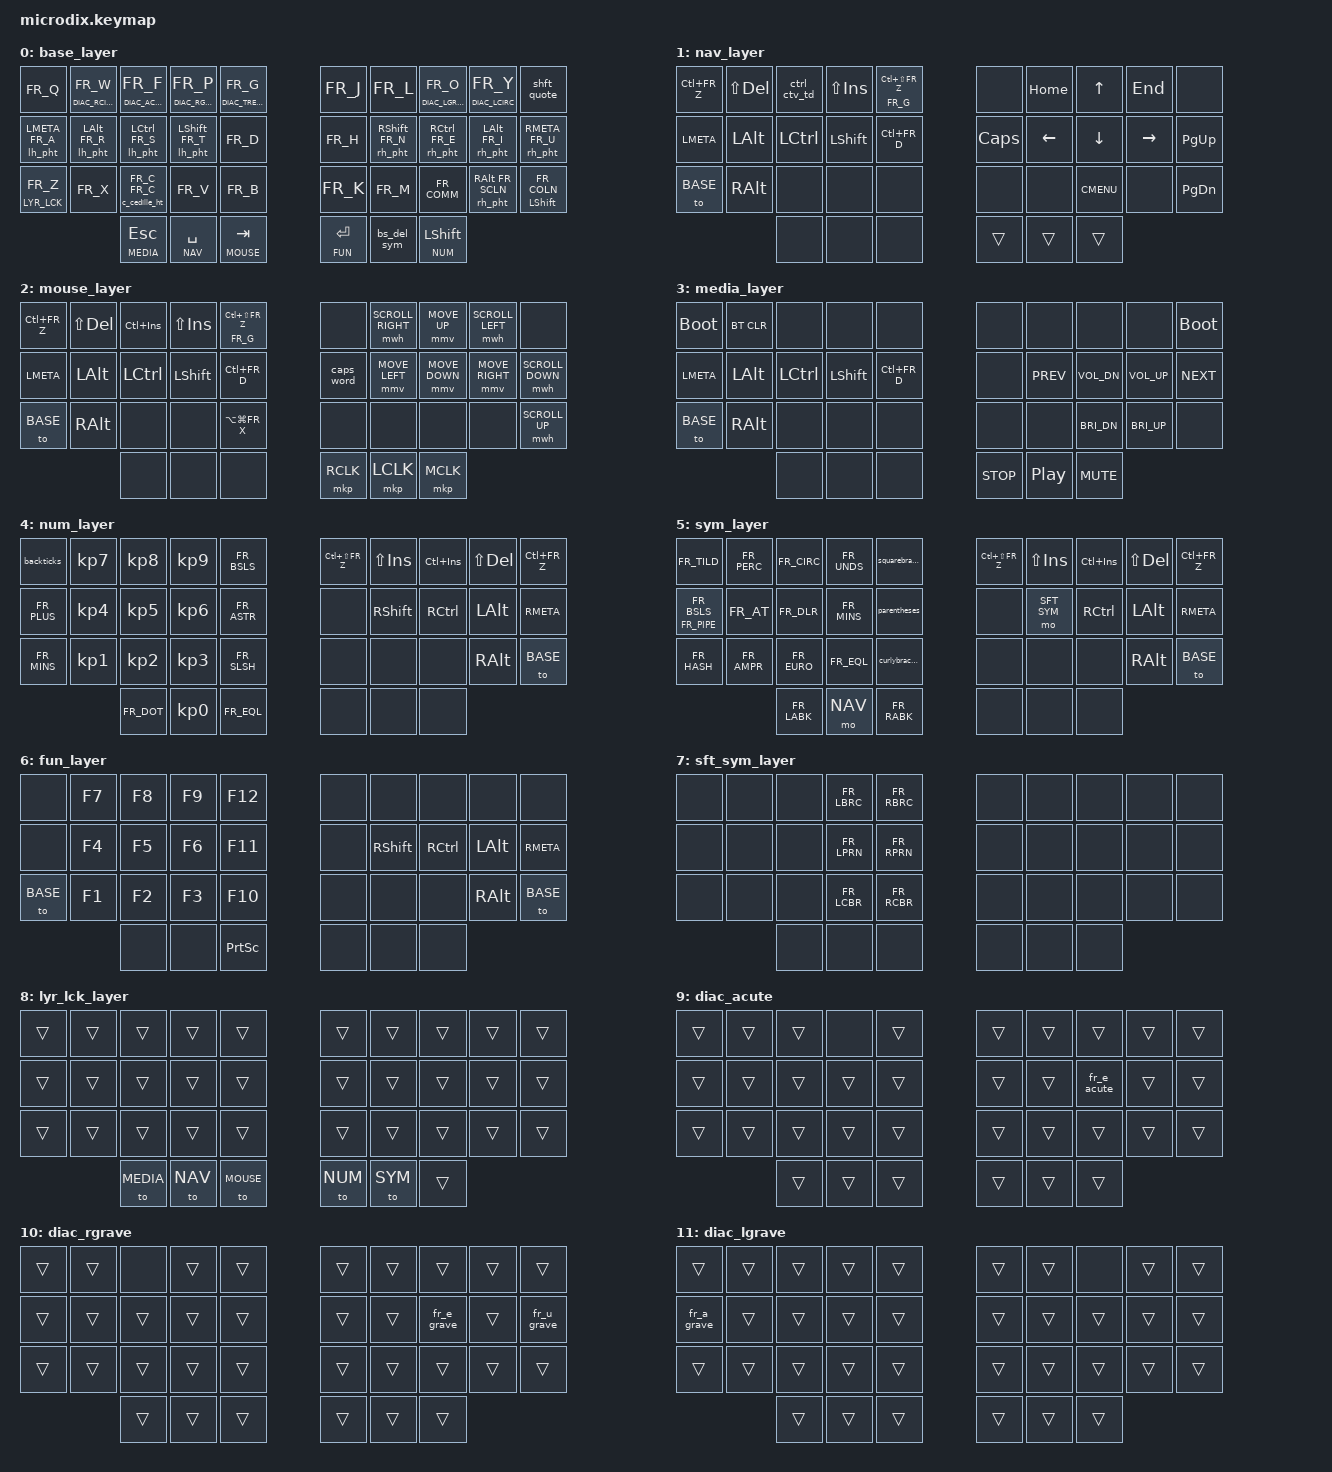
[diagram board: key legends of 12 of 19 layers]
/*
 * Copyright (c) 2020 The ZMK Contributors
 *
 * SPDX-License-Identifier: MIT
 */
#define HOST_OS 1
#include <behaviors.dtsi>
#include <dt-bindings/zmk/keys.h>
#include <dt-bindings/zmk/bt.h>
#include <dt-bindings/zmk/mouse.h>
#include "helper/keymap_french.h"
#include "helper/mouse.dtsi"
#include "../../../../zmk-nodefree-config/helper.h"
#include "../../../../zmk-nodefree-config/keypos_def/keypos_36keys.h"
#include "../../../../zmk-nodefree-config/international_chars/french.dtsi"
  
#define BASE       0
#define NAV        1
#define MOUSE      2
#define MEDIA      3
#define NUM        4
#define SYM        5
#define FUN        6
#define SFT_SYM    7
#define LYR_LCK    8
#define DIAC_ACUTE 9
#define DIAC_RGRAVE 10
#define DIAC_LGRAVE 11
#define DIAC_RCIRC 12
#define DIAC_LCIRC 13
#define DIAC_TREMA 14
#define SMART_CASE 15
#define CAMEL_CASE 16
#define SNAKE_CASE 17
#define KEBAB_CASE 18

#define KEYS_L LT0 LT1 LT2 LT3 LT4 LM0 LM1 LM2 LM3 LM4 LB0 LB1 LB2 LB3 LB4  // left-hand keys
#define KEYS_R RT0 RT1 RT2 RT3 RT4 RM0 RM1 RM2 RM3 RM4 RB0 RB1 RB2 RB3 RB4  // right-hand keys
#define THUMBS LH2 LH1 LH0 RH0 RH1 RH2                                      // thumb keys

#define ______ &trans
#define xxxxxx &none

#undef COMBO_TERM
#define COMBO_TERM 50

#define QUICK_TAP_MS 175

&mt {
    tapping-term-ms = <175>;
    flavor = "tap-preferred";
};

&sk {
     release-after-ms = <2000>;
     quick-release;
     ignore-modifiers;
};

&caps_word {
    continue-list = <UNDERSCORE MINUS BACKSPACE FR_M>;
};

// middle dot
ZMK_UNICODE_SINGLE(middle_dot, N0, N0, B, N7)

// open / close brackets
ZMK_BEHAVIOR(parentheses, macro,
	wait-ms = <0>;
	tap-ms = <5>;
	bindings = <&kp FR_LPRN>, <&kp FR_RPRN>, <&kp LEFT_ARROW>;
)
ZMK_BEHAVIOR(squarebrackets, macro,
	wait-ms = <0>;
	tap-ms = <5>;
	bindings = <&kp FR_LBRC>, <&kp FR_RBRC>, <&kp LEFT_ARROW>;
)
ZMK_BEHAVIOR(curlybrackets, macro,
	wait-ms = <0>;
	tap-ms = <5>;
	bindings = <&kp FR_LCBR>, <&kp FR_RCBR>, <&kp LEFT_ARROW>;
)
ZMK_BEHAVIOR(backticks, macro,
	wait-ms = <0>;
	tap-ms = <5>;
	bindings = <&kp RA(N7)>, <&kp RA(N7)>, <&kp LEFT_ARROW>;
)

// tap -> c | hold -> ç | hold + shift -> Ç
ZMK_BEHAVIOR(c_cedille_ht, hold_tap,
	flavor = "tap-preferred";
	tapping-term-ms = <175>;
	global-quick-tap;
	bindings = <&fr_c_cedilla>, <&kp>;
)

// y + ' -> !
ZMK_COMBO(combo_exlm, &kp FR_EXLM, RT3 RT4, BASE)

// , + ; -> middle dot
ZMK_COMBO(combo_middle_dot, &middle_dot, RB2 RB3, BASE)

// combo fun layer
ZMK_COMBO(combo_fun_layer, &mo FUN, LH0 RH0, BASE)

// combo smart case
ZMK_COMBO(combo_smart_layer, &mo SMART_CASE, LH2 RH2, BASE)

// combo scroll lock (compose key)
ZMK_COMBO(combo_compose_key, &kp SCROLLLOCK, LB2 LB1, BASE)

// tap -> ', shift tap -> "
ZMK_BEHAVIOR(shft_quote, mod_morph,
	bindings = <&kp FR_QUOT>, <&kp FR_DQUO>;
	mods = <(MOD_LSFT|MOD_RSFT)>;
)

// tap -> copy | double-tap -> copy + ctrl+f | triple-tap -> copy + ctrl+t, ctrl+v, enter
ZMK_BEHAVIOR(ctrl_ctv_td, tap_dance,
	tapping-term-ms = <175>;
	bindings = <&kp LC(INS)>, <&kp LC(FR_F)>, <&ctrl_c_t_v>;
)
ZMK_BEHAVIOR(ctrl_c_t_v, macro,
	wait-ms = <0>;
	tap-ms = <100>;
	bindings = <&kp LC(INS)>, <&kp LC(FR_T)>, <&kp LS(INS)>, <&kp ENTER>;
)

// tap -> backspace | rshft + tap: delete | hold: sym layer
ZMK_BEHAVIOR(bs_del_sym, mod_morph,
    bindings = <&lt SYM BSPC>, <&kp DEL>;
    mods = <(MOD_RSFT)>;
)

// home-row mods
ZMK_BEHAVIOR(lh_pht, hold_tap,  // left-hand HRMs
	flavor = "balanced";
	tapping-term-ms = <180>;
	quick-tap-ms = <QUICK_TAP_MS>;
	global-quick-tap-ms = <50>;        // requires PR #1387
	bindings = <&kp>, <&kp>;
	hold-trigger-key-positions = <KEYS_R THUMBS>;
	hold-trigger-on-release;            // requires PR #1423
)
ZMK_BEHAVIOR(rh_pht, hold_tap,  // right-hand HRMs
	flavor = "balanced";
	tapping-term-ms = <180>;
	quick-tap-ms = <QUICK_TAP_MS>;
	global-quick-tap-ms = <50>;        // requires PR #1387
	bindings = <&kp>, <&kp>;
	hold-trigger-key-positions = <KEYS_L THUMBS>;
	hold-trigger-on-release;            // requires PR #1423
)

/* keymap */

ZMK_LAYER(base_layer,
	&kp FR_Q				&lt DIAC_RCIRC FR_W		&lt DIAC_ACUTE FR_F			&lt DIAC_RGRAVE FR_P	&lt DIAC_TREMA FR_G				&kp FR_J		&kp FR_L				&lt DIAC_LGRAVE FR_O	&lt DIAC_LCIRC FR_Y		&shft_quote
	&lh_pht LMETA FR_A		&lh_pht LALT FR_R		&lh_pht LCTRL FR_S			&lh_pht LSHFT FR_T		&kp FR_D 						&kp FR_H		&rh_pht RSHFT FR_N		&rh_pht RCTRL FR_E		&rh_pht LALT FR_I		&rh_pht RMETA FR_U
	&lt LYR_LCK FR_Z		&kp FR_X				&c_cedille_ht FR_C FR_C		&kp FR_V				&kp FR_B 						&kp FR_K		&kp FR_M 				&kp FR_COMM				&rh_pht RALT FR_SCLN	&mt LSHIFT FR_COLN
													&lt MEDIA ESC 				&lt NAV SPACE			&lt MOUSE TAB					&lt FUN ENTER	&bs_del_sym				&lt NUM LSHFT
)
ZMK_LAYER(nav_layer,
	&kp LC(FR_Z)	&kp LS(DEL)		&ctrl_ctv_td	&kp LS(INS)		&mt FR_G LC(LS(FR_Z))			xxxxxx				&kp HOME			&kp UP_ARROW		&kp END				xxxxxx
	&kp LMETA 		&kp LALT		&kp LCTRL 		&kp LSHFT 		&kp LC(FR_D) 					&kp CAPSLOCK		&kp LEFT_ARROW		&kp DOWN_ARROW		&kp RIGHT_ARROW		&kp PG_UP
	&to BASE		&kp RALT		xxxxxx			xxxxxx			xxxxxx	 						xxxxxx				xxxxxx	 			&kp K_CMENU			xxxxxx				&kp PG_DN
									xxxxxx 			xxxxxx			xxxxxx							______				______				______
)
ZMK_LAYER(mouse_layer,
	&kp LC(FR_Z)	&kp LS(DEL)		&kp LC(INS)		&kp LS(INS)		&mt FR_G LC(LS(FR_Z))			xxxxxx			&mwh SCROLL_RIGHT	&mmv MOVE_UP		&mwh SCROLL_LEFT		xxxxxx
	&kp LMETA 		&kp LALT		&kp LCTRL 		&kp LSHFT 		&kp LC(FR_D) 					&caps_word		&mmv MOVE_LEFT	 	&mmv MOVE_DOWN		&mmv MOVE_RIGHT			&mwh SCROLL_DOWN
	&to BASE		&kp RALT		xxxxxx			xxxxxx			&kp LA(LG(FR_X))				xxxxxx			xxxxxx	 			xxxxxx				xxxxxx					&mwh SCROLL_UP
									xxxxxx 			xxxxxx			xxxxxx							&mkp RCLK		&mkp LCLK			&mkp MCLK
)
ZMK_LAYER(media_layer,
	&bootloader		&bt BT_CLR		xxxxxx			xxxxxx			xxxxxx					xxxxxx			xxxxxx			xxxxxx				xxxxxx				&bootloader
	&kp LMETA 		&kp LALT		&kp LCTRL 		&kp LSHFT 		&kp LC(FR_D) 			xxxxxx			&kp C_PREV		&kp C_VOL_DN		&kp C_VOL_UP		&kp C_NEXT
	&to BASE		&kp RALT		xxxxxx			xxxxxx			xxxxxx	 				xxxxxx			xxxxxx			&kp C_BRI_DN		&kp C_BRI_UP		xxxxxx
									xxxxxx 			xxxxxx			xxxxxx					&kp C_STOP		&kp C_PP		&kp C_MUTE
)
ZMK_LAYER(num_layer,
	&backticks		&kp KP_N7		&kp KP_N8		&kp KP_N9		&kp FR_BSLS				&kp LC(LS(FR_Z))	&kp LS(INS)		&kp LC(INS)		&kp LS(DEL)		&kp LC(FR_Z)
	&kp FR_PLUS		&kp KP_N4		&kp KP_N5 		&kp KP_N6 		&kp FR_ASTR 			xxxxxx				&kp RSHFT		&kp RCTRL		&kp LALT		&kp RMETA
	&kp FR_MINS		&kp KP_N1		&kp KP_N2		&kp KP_N3		&kp FR_SLSH				xxxxxx				xxxxxx			xxxxxx			&kp RALT		&to BASE
									&kp FR_DOT		&kp KP_N0		&kp FR_EQL				xxxxxx				xxxxxx			xxxxxx
)
ZMK_LAYER(sym_layer,
	&kp FR_TILD				&kp FR_PERC		&kp FR_CIRC		&kp FR_UNDS		&squarebrackets				&kp LC(LS(FR_Z))	&kp LS(INS)		&kp LC(INS)		&kp LS(DEL)		&kp LC(FR_Z)
	&mt FR_PIPE FR_BSLS		&kp FR_AT		&kp FR_DLR 		&kp FR_MINS		&parentheses				xxxxxx				&mo SFT_SYM		&kp RCTRL		&kp LALT		&kp RMETA
	&kp FR_HASH				&kp FR_AMPR		&kp FR_EURO		&kp FR_EQL		&curlybrackets				xxxxxx				xxxxxx			xxxxxx			&kp RALT		&to BASE
											&kp FR_LABK		&mo NAV			&kp FR_RABK					xxxxxx				xxxxxx			xxxxxx
)
ZMK_LAYER(fun_layer,
	xxxxxx		&kp F7		&kp F8		&kp F9		&kp F12			xxxxxx			xxxxxx			xxxxxx			xxxxxx			xxxxxx
	xxxxxx		&kp F4		&kp F5		&kp F6		&kp F11			xxxxxx			&kp RSHFT		&kp RCTRL		&kp LALT		&kp RMETA
	&to BASE	&kp F1		&kp F2		&kp F3		&kp F10			xxxxxx			xxxxxx			xxxxxx			&kp RALT		&to BASE
							xxxxxx		xxxxxx		&kp PSCRN		xxxxxx			xxxxxx			xxxxxx
)
ZMK_LAYER(sft_sym_layer,
	xxxxxx		xxxxxx		xxxxxx		&kp FR_LBRC		&kp FR_RBRC				xxxxxx		xxxxxx		xxxxxx		xxxxxx		xxxxxx
	xxxxxx		xxxxxx		xxxxxx		&kp FR_LPRN		&kp FR_RPRN				xxxxxx		xxxxxx		xxxxxx		xxxxxx		xxxxxx
	xxxxxx		xxxxxx		xxxxxx		&kp FR_LCBR		&kp FR_RCBR				xxxxxx		xxxxxx		xxxxxx		xxxxxx		xxxxxx
							xxxxxx		xxxxxx			xxxxxx					xxxxxx		xxxxxx		xxxxxx
)
ZMK_LAYER(lyr_lck_layer,
	______		______		______			______		______					______		______		______		______		______
	______		______		______			______		______					______		______		______		______		______
	______		______		______			______		______					______		______		______		______		______
							&to MEDIA 		&to NAV		&to MOUSE 				&to NUM		&to SYM		______
)
ZMK_LAYER(diac_acute,
	______		______		______		xxxxxx		______				______		______		______			______		______
	______		______		______		______		______				______		______		&fr_e_acute		______		______
	______		______		______		______		______				______		______		______			______		______
							______ 		______		______ 				______		______		______
)
ZMK_LAYER(diac_rgrave,
	______		______		xxxxxx		______		______				______		______		______			______		______
	______		______		______		______		______				______		______		&fr_e_grave		______		&fr_u_grave
	______		______		______		______		______				______		______		______			______		______
							______ 		______		______ 				______		______		______
)
ZMK_LAYER(diac_lgrave,
	______			______		______		______		______				______		______		xxxxxx		______		______
	&fr_a_grave		______		______		______		______				______		______		______		______		______
	______			______		______		______		______				______		______		______		______		______
								______ 		______		______ 				______		______		______
)
ZMK_LAYER(diac_rcirc,
	______		xxxxxx		______			______		______				______		______		&fr_o_circumflex	______				______
	______		______		______			______		______				______		______		&fr_e_circumflex	&fr_i_circumflex	&fr_u_circumflex
	______		______		______			______		______				______		______		______				______				______
							______ 			______		______ 				______		______		______
)
ZMK_LAYER(diac_lcirc,
	______				______		______		______		______				______		______		______		xxxxxx		______
	&fr_a_circumflex	______		______		______		______				______		______		______		______		______
	______				______		______		______		______				______		______		______		______		______
									______ 		______		______ 				______		______		______
)
ZMK_LAYER(diac_trema,
	______		______		______		______		xxxxxx				______		______		______				&fr_y_diaeresis		______
	______		______		______		______		______				______		______		&fr_e_diaeresis		&fr_i_diaeresis		&fr_u_diaeresis
	______		______		______		______		______				______		______		______				______				______
							______ 		______		______ 				______		______		______
)
ZMK_LAYER(smart_case,
	______		______				______		______		______				______				______		______		______		______
	______		______		&tog SNAKE_CASE		______		______				______				______		______		______		______
	______		______		&tog CAMEL_CASE		______		______				&tog KEBAB_CASE		______		______		______		______
									______ 		______		______ 				______				______		______
)
ZMK_LAYER(camel_case,
	______		______		______				______		______				______		______		______		______		______
	______		______		______				______		______				______		______		______		______		______
	______		______		______				______		______				______		______		______		______		______
							&tog CAMEL_CASE		&sk LSHFT	______ 				______		______		______
)
ZMK_LAYER(snake_case,
	______		______		______				______		______				______		______		______		______		______
	______		______		______				______		______				______		______		______		______		______
	______		______		______				______		______				______		______		______		______		______
							&tog SNAKE_CASE		&kp FR_UNDS	______ 				______		______		______
)
ZMK_LAYER(kebab_case,
	______		______		______				______		______				______		______		______		______		______
	______		______		______				______		______				______		______		______		______		______
	______		______		______				______		______				______		______		______		______		______
							&tog KEBAB_CASE		&kp FR_MINS	______ 				______		______		______
)
